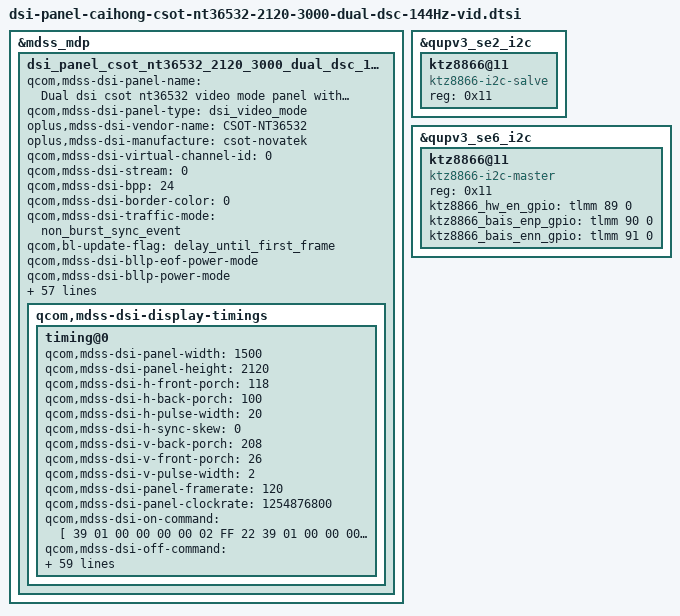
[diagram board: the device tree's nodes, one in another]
&mdss_mdp {
	dsi_panel_csot_nt36532_2120_3000_dual_dsc_144hz_vid: qcom,mdss_dsi_panel_csot_nt36532_2120_3000_dual_dsc_144hz_vid {
		qcom,mdss-dsi-panel-name = "Dual dsi csot nt36532 video mode panel with DSC";
		qcom,mdss-dsi-panel-type = "dsi_video_mode";
		oplus,mdss-dsi-vendor-name = "CSOT-NT36532";
		oplus,mdss-dsi-manufacture = "csot-novatek";
		qcom,mdss-dsi-virtual-channel-id = <0>;
		qcom,mdss-dsi-stream = <0>;
		qcom,mdss-dsi-bpp = <24>;
		qcom,mdss-dsi-border-color = <0>;
		qcom,mdss-dsi-traffic-mode = "non_burst_sync_event";
		qcom,bl-update-flag = "delay_until_first_frame";
		qcom,mdss-dsi-bllp-eof-power-mode;
		qcom,mdss-dsi-bllp-power-mode;
		qcom,mdss-dsi-lane-0-state;
		qcom,mdss-dsi-lane-1-state;
		qcom,mdss-dsi-lane-2-state;
		qcom,mdss-dsi-lane-3-state;
		qcom,mdss-dsi-dma-trigger = "trigger_sw";
		qcom,mdss-dsi-mdp-trigger = "none";
		qcom,mdss-dsi-tx-eot-append;
		qcom,mdss-dsi-lp11-init;
		qcom,mdss-dsi-reset-sequence = <1 10>, <0 5>, <1 10>;
		qcom,mdss-pan-physical-width-dimension = <250>;
		qcom,mdss-pan-physical-height-dimension = <177>;
		/* HDR Setting */
		qcom,mdss-dsi-panel-hdr-enabled;
		qcom,mdss-dsi-panel-hdr-color-primaries = <15635 16450 34000 16000 13250 34500 7500 3000>;
		qcom,mdss-dsi-panel-peak-brightness = <5400000>;
		qcom,mdss-dsi-panel-average-brightness = <2000000>;
		qcom,mdss-dsi-panel-blackness-level = <2047>;

		qcom,mdss-dsi-display-timings {
			timing@0 {
				qcom,mdss-dsi-panel-width = <1500>;
				qcom,mdss-dsi-panel-height = <2120>;
				qcom,mdss-dsi-h-front-porch = <118>;
				qcom,mdss-dsi-h-back-porch = <100>;
				qcom,mdss-dsi-h-pulse-width = <20>;
				qcom,mdss-dsi-h-sync-skew = <0>;
				qcom,mdss-dsi-v-back-porch = <208>;
				qcom,mdss-dsi-v-front-porch = <26>;
				qcom,mdss-dsi-v-pulse-width = <2>;
				qcom,mdss-dsi-panel-framerate = <120>;
				qcom,mdss-dsi-panel-clockrate = <1254876800>;

				qcom,mdss-dsi-on-command = [
					39 01 00 00 00 00 02 FF 22
					39 01 00 00 00 00 02 FB 01
					39 01 00 00 00 00 02 2D 01

					39 01 00 00 00 00 02 FF 24
					39 01 00 00 00 00 02 FB 01
					39 01 00 00 00 00 07 BC 00 00 03 22 00 41

					15 01 00 00 00 00 02 FF 23
					15 01 00 00 00 00 02 FB 01
					15 01 00 00 00 00 02 00 60
					15 01 00 00 00 00 02 07 20
					15 01 00 00 00 00 02 08 01
					15 01 00 00 00 00 02 09 5A
					15 01 00 00 00 00 02 10 0C
					15 01 00 00 00 00 02 11 03
					15 01 00 00 00 00 02 12 E1
					15 01 00 00 00 00 02 15 A9
					15 01 00 00 00 00 02 16 16
					15 01 00 00 00 00 02 0A 8E
					15 01 00 00 00 00 02 0B 8E
					15 01 00 00 00 00 02 0C 8E
					15 01 00 00 00 00 02 0D 00
					15 01 00 00 00 00 02 19 00
					15 01 00 00 00 00 02 1A 04
					15 01 00 00 00 00 02 1B 08
					15 01 00 00 00 00 02 1C 0C
					15 01 00 00 00 00 02 1D 10
					15 01 00 00 00 00 02 1E 14
					15 01 00 00 00 00 02 1F 18
					15 01 00 00 00 00 02 20 1C
					15 01 00 00 00 00 02 21 20
					15 01 00 00 00 00 02 22 24
					15 01 00 00 00 00 02 23 28
					15 01 00 00 00 00 02 24 2C
					15 01 00 00 00 00 02 25 30
					15 01 00 00 00 00 02 26 34
					15 01 00 00 00 00 02 27 38
					15 01 00 00 00 00 02 28 3C
					15 01 00 00 00 00 02 2A 20
					15 01 00 00 00 00 02 2B 20
					15 01 00 00 00 00 02 30 FF
					15 01 00 00 00 00 02 31 FD
					15 01 00 00 00 00 02 32 FC
					15 01 00 00 00 00 02 33 FA
					15 01 00 00 00 00 02 34 F8
					15 01 00 00 00 00 02 35 F6
					15 01 00 00 00 00 02 36 F4
					15 01 00 00 00 00 02 37 F2
					15 01 00 00 00 00 02 38 F0
					15 01 00 00 00 00 02 39 EE
					15 01 00 00 00 00 02 3A EC
					15 01 00 00 00 00 02 3B EA
					15 01 00 00 00 00 02 3D E9
					15 01 00 00 00 00 02 3F E8
					15 01 00 00 00 00 02 40 E7
					15 01 00 00 00 00 02 41 E6
					15 01 00 00 00 00 02 45 FF
					15 01 00 00 00 00 02 46 F9
					15 01 00 00 00 00 02 47 F6
					15 01 00 00 00 00 02 48 F2
					15 01 00 00 00 00 02 49 F0
					15 01 00 00 00 00 02 4A EC
					15 01 00 00 00 00 02 4B E8
					15 01 00 00 00 00 02 4C E4
					15 01 00 00 00 00 02 4D E0
					15 01 00 00 00 00 02 4E DE
					15 01 00 00 00 00 02 4F D9
					15 01 00 00 00 00 02 50 D6
					15 01 00 00 00 00 02 51 D4
					15 01 00 00 00 00 02 52 C2
					15 01 00 00 00 00 02 53 D0
					15 01 00 00 00 00 02 54 CD
					15 01 00 00 00 00 02 58 FF
					15 01 00 00 00 00 02 59 F6
					15 01 00 00 00 00 02 5A F0
					15 01 00 00 00 00 02 5B EB
					15 01 00 00 00 00 02 5C E8
					15 01 00 00 00 00 02 5D E5
					15 01 00 00 00 00 02 5E E3
					15 01 00 00 00 00 02 5F E0
					15 01 00 00 00 00 02 60 DE
					15 01 00 00 00 00 02 61 DA
					15 01 00 00 00 00 02 62 D7
					15 01 00 00 00 00 02 63 D4
					15 01 00 00 00 00 02 64 D2
					15 01 00 00 00 00 02 65 D0
					15 01 00 00 00 00 02 66 CC
					15 01 00 00 00 00 02 67 C8

					39 01 00 00 00 00 02 FF 27
					39 01 00 00 00 00 02 FB 01
					39 01 00 00 00 00 02 30 F0
					39 01 00 00 00 00 03 31 2A 00
					39 01 00 00 00 00 02 D0 31
					39 01 00 00 00 00 02 D1 54
					39 01 00 00 00 00 02 DE 40
					39 01 00 00 00 00 02 DF 02

					39 01 00 00 00 00 02 FF 2A
					39 01 00 00 00 00 02 FB 01
					39 01 00 00 00 00 02 C4 02

					39 01 00 00 00 00 02 FF F0
					39 01 00 00 00 00 02 FB 01
					39 01 00 00 00 00 02 FA 05
					39 01 00 00 00 00 02 76 16

					39 01 00 00 00 00 02 FF 23
					39 01 00 00 00 00 02 FB 01
					39 01 00 00 00 00 03 BA AA 2A
					39 01 00 00 00 00 03 BB A0 2A
					39 01 00 00 00 00 02 FF 27
					39 01 00 00 00 00 02 FB 01
					39 01 00 00 00 00 02 01 8C

					39 01 00 00 00 00 02 FF 10
					39 01 00 00 00 00 02 FB 01
					39 01 00 00 00 00 03 51 07 FF
					39 01 00 00 00 00 02 53 2C
					39 01 00 00 00 00 02 B9 00
					39 01 00 00 00 00 02 55 01
					39 01 00 00 00 00 02 B9 02
					39 01 00 00 00 00 07 3B 03 D2 1A 04 04 00
					39 01 00 00 00 00 02 90 03
					39 01 00 00 00 00 11 91 89 A8 00 14 D2 00 00 00 02 1E 00 0A 05 7A 03 AA
					39 01 00 00 00 00 03 92 10 F0
					39 01 00 00 00 00 02 9D 01
					39 01 00 00 00 00 02 B2 91
					39 01 00 00 00 00 02 B3 40

					15 01 00 00 78 00 02 11 00
					15 01 00 00 0A 00 02 29 00
				];
				qcom,mdss-dsi-off-command = [
					15 01 00 00 0A 00 02 28 00
					15 01 00 00 41 00 02 10 00
				];
				qcom,mdss-dsi-on-command-state = "dsi_lp_mode";
				qcom,mdss-dsi-off-command-state = "dsi_lp_mode";
 				qcom,mdss-dsi-cabc-ui-command = [
					39 00 00 40 00 00 02 B9 00
					39 00 00 40 00 00 02 55 01
					39 00 00 00 00 00 02 B9 02
 				];
 				qcom,mdss-dsi-cabc-still-image-command = [
					39 00 00 40 00 00 02 B9 00
					39 00 00 40 00 00 02 55 02
					39 00 00 00 00 00 02 B9 02
 				];
 				qcom,mdss-dsi-cabc-video-command = [
					39 00 00 40 00 00 02 B9 00
					39 00 00 40 00 00 02 55 03
					39 00 00 00 00 00 02 B9 02
 				];
 				qcom,mdss-dsi-cabc-off-command = [
 					39 00 00 40 00 00 02 B9 00
 					39 00 00 40 00 00 02 55 00
 					39 00 00 00 00 00 02 B9 02
 				];
 				qcom,mdss-dsi-cabc-ui-command-state = "dsi_hs_mode";
 				qcom,mdss-dsi-cabc-still-image-command-state = "dsi_hs_mode";
 				qcom,mdss-dsi-cabc-video-command-state = "dsi_hs_mode";
 				qcom,mdss-dsi-cabc-off-command-state = "dsi_hs_mode";
				qcom,mdss-dsi-h-sync-pulse = <0>;
				qcom,compression-mode = "dsc";
				qcom,mdss-dsc-version = <0x12>;
				qcom,mdss-dsc-encoders = <1>;
				qcom,mdss-dsc-slice-height = <20>;
				qcom,mdss-dsc-slice-width = <750>;
				qcom,mdss-dsc-slice-per-pkt = <2>;
				qcom,mdss-dsc-bit-per-component = <8>;
				qcom,mdss-dsc-bit-per-pixel = <8>;
				qcom,mdss-dsc-block-prediction-enable;
			};
		};
	};
};

&dsi_panel_csot_nt36532_2120_3000_dual_dsc_144hz_vid {
	qcom,panel-supply-entries = <&oplus_dsi_panel_custom_pwr_supply>;
	qcom,dsi-ctrl-num = <0 1>;
	qcom,dsi-phy-num = <0 1>;
	qcom,dsi-select-clocks = "pll_byte_clk0", "pll_dsi_clk0";
	qcom,mdss-dsi-bl-pmic-control-type = "bl_ctrl_external";
	qcom,mdss-dsi-bl-min-level = <2>;
	qcom,mdss-dsi-bl-max-level = <2047>;
	qcom,mdss-brightness-max-level = <2047>;
	qcom,mdss-dsi-bl-inverted-dbv;
	oplus,dsi-brightness-default-level = <913>;
	qcom,platform-reset-gpio = <&tlmm 133 0>;
	qcom,esd-check-enabled;
	qcom,mdss-dsi-panel-status-check-mode = "error_flag";
	qcom,error-flag-gpio = <&tlmm 86 0>;
	qcom,error-flag-gpio-slave = <&tlmm 43 0>;
	oplus,bl-use-ktz8866-ic-ctrl;
	oplus,dp-enabled;
	oplus,dsi-cabc-enabled;

	//enable mipi strength
	oplus,enhance_mipi_strength;
	oplus,vreg_ctrl_flag;

	qcom,mdss-dsi-pan-enable-dynamic-fps;
	qcom,mdss-dsi-pan-fps-update = "dfps_immediate_porch_mode_both_hv_porch";
	qcom,dsi-supported-dfps-list = <120 144 90  60   50   48   30>;
	qcom,dsi-dfps-hfp-list       = <118 57  118 118  118  118  118>;
	qcom,dsi-dfps-hbp-list       = <100 38  100 100  100  100  100>;
	qcom,dsi-dfps-hpw-list       = <20  20  20  20   20   20   20>;
	qcom,dsi-dfps-vbp-list       = <208 208 208 208  208  208  208>;
	qcom,dsi-dfps-vfp-list       = <26  26  811 2382 3324 3560 7094>;
	qcom,dsi-dfps-vpw-list       = <2   2   2   2    2    2    2>;

	qcom,mdss-dsi-display-timings {
		timing@0 {
			qcom,mdss-dsi-fps-switch-120-command = [
				39 00 00 40 00 00 02 B2 91
				39 00 00 00 00 00 02 B3 40
			];
			qcom,mdss-dsi-fps-switch-60-command = [
				39 00 00 40 00 00 02 B2 91
				39 00 00 00 00 00 02 B3 40
			];
			qcom,mdss-dsi-fps-switch-30-command = [
				39 00 00 40 00 00 02 B2 91
				39 00 00 00 00 00 02 B3 40
			];
			qcom,mdss-dsi-fps-switch-90-command = [
				39 00 00 40 00 00 02 B2 00
				39 00 00 00 00 00 02 B3 80
			];
			qcom,mdss-dsi-fps-switch-50-command = [
				39 00 00 40 00 00 02 B2 00
				39 00 00 00 00 00 02 B3 80
			];
			qcom,mdss-dsi-fps-switch-48-command = [
				39 00 00 40 00 00 02 B2 00
				39 00 00 00 00 00 02 B3 80
			];
			qcom,mdss-dsi-fps-switch-144-command = [
				39 00 00 40 00 00 02 B2 00
				39 00 00 00 00 00 02 B3 00
			];
			qcom,display-topology = <4 4 2>;
			qcom,default-topology-index = <0>;
			qcom,mdss-dsi-fps-switch-120-command-state = "dsi_lp_mode";
			qcom,mdss-dsi-fps-switch-60-command-state = "dsi_lp_mode";
			qcom,mdss-dsi-fps-switch-30-command-state = "dsi_lp_mode";
			qcom,mdss-dsi-fps-switch-90-command-state = "dsi_lp_mode";
			qcom,mdss-dsi-fps-switch-50-command-state = "dsi_lp_mode";
			qcom,mdss-dsi-fps-switch-48-command-state = "dsi_lp_mode";
			qcom,mdss-dsi-fps-switch-144-command-state = "dsi_lp_mode";
		};
	};
};

&qupv3_se2_i2c {
	status = "ok";
	ktz8866@11 {
		compatible = "ktz8866-i2c-salve";
		reg = <0x11>;
	};
};

&qupv3_se6_i2c {
	status = "ok";
	ktz8866@11 {
		compatible = "ktz8866-i2c-master";
		reg = <0x11>;
		ktz8866_hw_en_gpio = <&tlmm 89 0>;
		ktz8866_bais_enp_gpio = <&tlmm 90 0>;
		ktz8866_bais_enn_gpio = <&tlmm 91 0>;
	};
};
